# max32570 register map
Vendor: Maxim-Integrated; Series: ARMCM4; File version: 1.0
CPU: CM4 r2p1, little endian, MPU, FPU, 3 interrupt priority bits
Registers are 32-bit, read-write, reset 0x0 unless marked. A register's access mark holds for its fields unless they carry their own. Offsets are from the block's base; [hi:lo] are bit positions; {n}, {i} and the like mark numbered series.

## ADC — 10-bit Analog to Digital Converter
Base 0x40034000
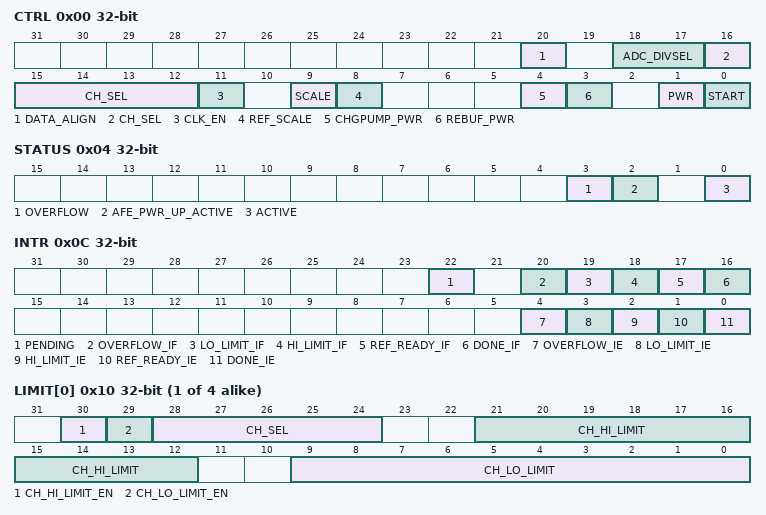
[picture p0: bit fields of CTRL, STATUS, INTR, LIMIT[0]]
0x00 CTRL — ADC Control
  [20] DATA_ALIGN — ADC Data Alignment Select
  [18:17] ADC_DIVSEL — Scales the external inputs, all inputs are scaled the same
    {v}=DIV{v+1} (v=0..3)
  [16:12] CH_SEL — ADC Channel Select
    {v}=AIN{v} (v=0..7); 8=VcoreA; 9=VcoreB; 10=Vrxout; 11=Vtxout; 12=VddA; 13=VddB/4; 14=Vddio/4; 15=Vddioh/4; 16=VregI/4
  [11] CLK_EN — ADC Clock Enable
  [9] SCALE — ADC Scale
  [8] REF_SCALE — ADC Reference Scale
  [4] CHGPUMP_PWR — ADC Charge Pump Power Up
  [3] REBUF_PWR — ADC Reference Buffer Power Up
  [1] PWR — ADC Power Up
  [0] START — Start ADC Conversion
0x04 STATUS — ADC Status
  [3] OVERFLOW ro — ADC Overflow
  [2] AFE_PWR_UP_ACTIVE ro — AFE Power Up Delay Active
  [0] ACTIVE ro — ADC Conversion In Progress
0x08 DATA — ADC Output Data
  [15:0] DATA ro — ADC Converted Sample Data Output
0x0C INTR — ADC Interrupt Control Register
  [22] PENDING ro — ADC Interrupt Pending Status
  [20] OVERFLOW_IF write-1-clears — ADC Overflow Interrupt Flag
  [19] LO_LIMIT_IF write-1-clears — ADC Lo Limit Monitor Interrupt Flag
  [18] HI_LIMIT_IF write-1-clears — ADC Hi Limit Monitor Interrupt Flag
  [17] REF_READY_IF write-1-clears — ADC Reference Ready Interrupt Flag
  [16] DONE_IF write-1-clears — ADC Done Interrupt Flag
  [4] OVERFLOW_IE — ADC Overflow Interrupt Enable
  [3] LO_LIMIT_IE — ADC Lo Limit Monitor Interrupt Enable
  [2] HI_LIMIT_IE — ADC Hi Limit Monitor Interrupt Enable
  [1] REF_READY_IE — ADC Reference Ready Interrupt Enable
  [0] DONE_IE — ADC Done Interrupt Enable
{0x10+4i} LIMIT[{i}] (i=0..3) — ADC Limit
  [30] CH_HI_LIMIT_EN — High Limit Monitoring Enable
  [29] CH_LO_LIMIT_EN — Low Limit Monitoring Enable
  [28:24] CH_SEL — ADC Channel Select
  [21:12] CH_HI_LIMIT — High Limit Threshold
  [9:0] CH_LO_LIMIT — Low Limit Threshold

## AESKEYS
Base 0x40005000
0x00 SRAM_KEY — AES SRAM KEY
0x20 CODE_KEY — AES CODE Key
0x40 DATA_KEY — AES DATA KEY

## FCR — Function Control Register.
Base 0x40000800
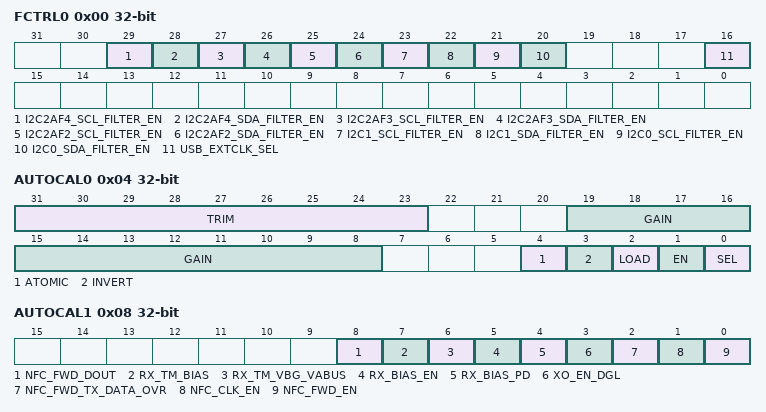
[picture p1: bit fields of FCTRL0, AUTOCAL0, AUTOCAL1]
0x00 FCTRL0 — Register 0.
  [29] I2C2AF4_SCL_FILTER_EN — I2C2 AF4 SCL Glitch Filter Enable
    0=dis (Filter disabled.); 1=en (Filter enabled.)
  [28] I2C2AF4_SDA_FILTER_EN — I2C2 AF4 SDA Glitch Filter Enable
    0=dis (Filter disabled.); 1=en (Filter enabled.)
  [27] I2C2AF3_SCL_FILTER_EN — I2C2 AF3 SCL Glitch Filter Enable.
    0=dis (Filter disabled.); 1=en (Filter enabled.)
  [26] I2C2AF3_SDA_FILTER_EN — I2C2 AF3 SDA Glitch Filter Enable.
    0=dis (Filter disabled.); 1=en (Filter enabled.)
  [25] I2C2AF2_SCL_FILTER_EN — I2C2 AF2 SCL Glitch Filter Enable.
    0=dis (Filter disabled.); 1=en (Filter enabled.)
  [24] I2C2AF2_SDA_FILTER_EN — I2C2 AF2 SDA Glitch Filter Enable.
    0=dis (Filter disabled.); 1=en (Filter enabled.)
  [23] I2C1_SCL_FILTER_EN — I2C1 SCL Glitch Filter Enable.
    0=dis (Filter disabled.); 1=en (Filter enabled.)
  [22] I2C1_SDA_FILTER_EN — I2C1 SDA Glitch Filter Enable.
    0=dis (Filter disabled.); 1=en (Filter enabled.)
  [21] I2C0_SCL_FILTER_EN — I2C0 SCL Glitch Filter Enable.
    0=dis (Filter disabled.); 1=en (Filter enabled.)
  [20] I2C0_SDA_FILTER_EN — I2C0 SDA Glitch Filter Enable.
    0=dis (Filter disabled.); 1=en (Filter enabled.)
  [16] USB_EXTCLK_SEL — USB External Core Clock Select.
    0=sys (Generated clock from system clock.); 1=dig (Digital clock from a GPIO.)
0x04 AUTOCAL0 — Register 1.
  [31:23] TRIM — 150MHz HFIO Auto Calibration Trim
  [19:8] GAIN — MU value.
  [4] ATOMIC — Atomic mode.
    0=not (Not Running.); 1=run (Running.)
  [3] INVERT — Invert Gain.
    0=not (Not Running.); 1=run (Running.)
  [2] LOAD — Load Trim.
  [1] EN — Autocalibration Run.
    0=not (Not Running.); 1=run (Running.)
  [0] SEL — Auto-calibration Enable.
    0=dis (Disabled.); 1=en (Enabled.)
0x08 AUTOCAL1 — Register 2.
  [8] NFC_FWD_DOUT — FWD output from FNC block
  [7] RX_TM_BIAS
  [6] RX_TM_VBG_VABUS
  [5] RX_BIAS_EN — Enable the NFC receiver analog blocks
  [4] RX_BIAS_PD — Power down enable for NFC receiver analog block
  [3] XO_EN_DGL
  [2] NFC_FWD_TX_DATA_OVR — FWD input for NFC block
  [1] NFC_CLK_EN — Enabled the NFC blocks clock divider in Analog
  [0] NFC_FWD_EN — Enabled FWD mode for NFC block
0x0C AUTOCAL2 — Register 3.
  [7:0] RUNTIME — Automatic Calibration Run Time.
